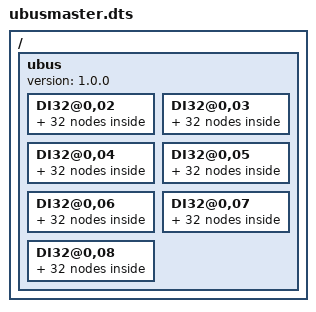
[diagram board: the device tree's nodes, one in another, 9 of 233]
/dts-v1/;
/{
ubus {
	version = "1.0.0";
	DI32@0,02 {
		vname = "0002_DI32/i";
		ts_vname = "DI32@0,02";
		kind = <0x0>;
		 0 { method = <2>; debounce = <10>; T_acc = <0>; N_acc = <2>; T_relax = <50>; invert = <0>; };
		 1 { method = <2>; debounce = <10>; T_acc = <0>; N_acc = <2>; T_relax = <50>; invert = <0>; };
		 2 { method = <2>; debounce = <10>; T_acc = <0>; N_acc = <2>; T_relax = <50>; invert = <0>; };
		 3 { method = <2>; debounce = <10>; T_acc = <0>; N_acc = <2>; T_relax = <50>; invert = <0>; };
		 4 { method = <2>; debounce = <10>; T_acc = <0>; N_acc = <2>; T_relax = <50>; invert = <0>; };
		 5 { method = <2>; debounce = <10>; T_acc = <0>; N_acc = <2>; T_relax = <50>; invert = <0>; };
		 6 { method = <2>; debounce = <10>; T_acc = <0>; N_acc = <2>; T_relax = <50>; invert = <0>; };
		 7 { method = <2>; debounce = <10>; T_acc = <0>; N_acc = <2>; T_relax = <50>; invert = <0>; };
		 8 { method = <2>; debounce = <10>; T_acc = <0>; N_acc = <2>; T_relax = <50>; invert = <0>; };
		 9 { method = <2>; debounce = <10>; T_acc = <0>; N_acc = <2>; T_relax = <50>; invert = <0>; };
		10 { method = <2>; debounce = <10>; T_acc = <0>; N_acc = <2>; T_relax = <50>; invert = <0>; };
		11 { method = <2>; debounce = <10>; T_acc = <0>; N_acc = <2>; T_relax = <50>; invert = <0>; };
		12 { method = <2>; debounce = <10>; T_acc = <0>; N_acc = <2>; T_relax = <50>; invert = <0>; };
		13 { method = <2>; debounce = <10>; T_acc = <0>; N_acc = <2>; T_relax = <50>; invert = <0>; };
		14 { method = <2>; debounce = <10>; T_acc = <0>; N_acc = <2>; T_relax = <50>; invert = <0>; };
		15 { method = <2>; debounce = <10>; T_acc = <0>; N_acc = <2>; T_relax = <50>; invert = <0>; };
		16 { method = <2>; debounce = <10>; T_acc = <0>; N_acc = <2>; T_relax = <50>; invert = <0>; };
		17 { method = <2>; debounce = <10>; T_acc = <0>; N_acc = <2>; T_relax = <50>; invert = <0>; };
		18 { method = <2>; debounce = <10>; T_acc = <0>; N_acc = <2>; T_relax = <50>; invert = <0>; };
		19 { method = <2>; debounce = <10>; T_acc = <0>; N_acc = <2>; T_relax = <50>; invert = <0>; };
		20 { method = <2>; debounce = <10>; T_acc = <0>; N_acc = <2>; T_relax = <50>; invert = <0>; };
		21 { method = <2>; debounce = <10>; T_acc = <0>; N_acc = <2>; T_relax = <50>; invert = <0>; };
		22 { method = <2>; debounce = <10>; T_acc = <0>; N_acc = <2>; T_relax = <50>; invert = <0>; };
		23 { method = <2>; debounce = <10>; T_acc = <0>; N_acc = <2>; T_relax = <50>; invert = <0>; };
		24 { method = <2>; debounce = <10>; T_acc = <0>; N_acc = <2>; T_relax = <50>; invert = <0>; };
		25 { method = <2>; debounce = <10>; T_acc = <0>; N_acc = <2>; T_relax = <50>; invert = <0>; };
		26 { method = <2>; debounce = <10>; T_acc = <0>; N_acc = <2>; T_relax = <50>; invert = <0>; };
		27 { method = <2>; debounce = <10>; T_acc = <0>; N_acc = <2>; T_relax = <50>; invert = <0>; };
		28 { method = <2>; debounce = <10>; T_acc = <0>; N_acc = <2>; T_relax = <50>; invert = <0>; };
		29 { method = <2>; debounce = <10>; T_acc = <0>; N_acc = <2>; T_relax = <50>; invert = <0>; };
		30 { method = <2>; debounce = <10>; T_acc = <0>; N_acc = <2>; T_relax = <50>; invert = <0>; };
		31 { method = <2>; debounce = <10>; T_acc = <0>; N_acc = <2>; T_relax = <50>; invert = <0>; }; };
	DI32@0,03 {
		vname = "0003_DI32/i";
		ts_vname = "DI32@0,03";
		kind = <0x0>;
		 0 { method = <2>; debounce = <10>; T_acc = <0>; N_acc = <2>; T_relax = <50>; invert = <0>; };
		 1 { method = <2>; debounce = <10>; T_acc = <0>; N_acc = <2>; T_relax = <50>; invert = <0>; };
		 2 { method = <2>; debounce = <10>; T_acc = <0>; N_acc = <2>; T_relax = <50>; invert = <0>; };
		 3 { method = <2>; debounce = <10>; T_acc = <0>; N_acc = <2>; T_relax = <50>; invert = <0>; };
		 4 { method = <2>; debounce = <10>; T_acc = <0>; N_acc = <2>; T_relax = <50>; invert = <0>; };
		 5 { method = <2>; debounce = <10>; T_acc = <0>; N_acc = <2>; T_relax = <50>; invert = <0>; };
		 6 { method = <2>; debounce = <10>; T_acc = <0>; N_acc = <2>; T_relax = <50>; invert = <0>; };
		 7 { method = <2>; debounce = <10>; T_acc = <0>; N_acc = <2>; T_relax = <50>; invert = <0>; };
		 8 { method = <2>; debounce = <10>; T_acc = <0>; N_acc = <2>; T_relax = <50>; invert = <0>; };
		 9 { method = <2>; debounce = <10>; T_acc = <0>; N_acc = <2>; T_relax = <50>; invert = <0>; };
		10 { method = <2>; debounce = <10>; T_acc = <0>; N_acc = <2>; T_relax = <50>; invert = <0>; };
		11 { method = <2>; debounce = <10>; T_acc = <0>; N_acc = <2>; T_relax = <50>; invert = <0>; };
		12 { method = <2>; debounce = <10>; T_acc = <0>; N_acc = <2>; T_relax = <50>; invert = <0>; };
		13 { method = <2>; debounce = <10>; T_acc = <0>; N_acc = <2>; T_relax = <50>; invert = <0>; };
		14 { method = <2>; debounce = <10>; T_acc = <0>; N_acc = <2>; T_relax = <50>; invert = <0>; };
		15 { method = <2>; debounce = <10>; T_acc = <0>; N_acc = <2>; T_relax = <50>; invert = <0>; };
		16 { method = <2>; debounce = <10>; T_acc = <0>; N_acc = <2>; T_relax = <50>; invert = <0>; };
		17 { method = <2>; debounce = <10>; T_acc = <0>; N_acc = <2>; T_relax = <50>; invert = <0>; };
		18 { method = <2>; debounce = <10>; T_acc = <0>; N_acc = <2>; T_relax = <50>; invert = <0>; };
		19 { method = <2>; debounce = <10>; T_acc = <0>; N_acc = <2>; T_relax = <50>; invert = <0>; };
		20 { method = <2>; debounce = <10>; T_acc = <0>; N_acc = <2>; T_relax = <50>; invert = <0>; };
		21 { method = <2>; debounce = <10>; T_acc = <0>; N_acc = <2>; T_relax = <50>; invert = <0>; };
		22 { method = <2>; debounce = <10>; T_acc = <0>; N_acc = <2>; T_relax = <50>; invert = <0>; };
		23 { method = <2>; debounce = <10>; T_acc = <0>; N_acc = <2>; T_relax = <50>; invert = <0>; };
		24 { method = <2>; debounce = <10>; T_acc = <0>; N_acc = <2>; T_relax = <50>; invert = <0>; };
		25 { method = <2>; debounce = <10>; T_acc = <0>; N_acc = <2>; T_relax = <50>; invert = <0>; };
		26 { method = <2>; debounce = <10>; T_acc = <0>; N_acc = <2>; T_relax = <50>; invert = <0>; };
		27 { method = <2>; debounce = <10>; T_acc = <0>; N_acc = <2>; T_relax = <50>; invert = <0>; };
		28 { method = <2>; debounce = <10>; T_acc = <0>; N_acc = <2>; T_relax = <50>; invert = <0>; };
		29 { method = <2>; debounce = <10>; T_acc = <0>; N_acc = <2>; T_relax = <50>; invert = <0>; };
		30 { method = <2>; debounce = <10>; T_acc = <0>; N_acc = <2>; T_relax = <50>; invert = <0>; };
		31 { method = <2>; debounce = <10>; T_acc = <0>; N_acc = <2>; T_relax = <50>; invert = <0>; }; };
	DI32@0,04 {
		vname = "0004_DI32/i";
		ts_vname = "DI32@0,04";
		kind = <0x0>;
		 0 { method = <2>; debounce = <10>; T_acc = <0>; N_acc = <2>; T_relax = <50>; invert = <0>; };
		 1 { method = <2>; debounce = <10>; T_acc = <0>; N_acc = <2>; T_relax = <50>; invert = <0>; };
		 2 { method = <2>; debounce = <10>; T_acc = <0>; N_acc = <2>; T_relax = <50>; invert = <0>; };
		 3 { method = <2>; debounce = <10>; T_acc = <0>; N_acc = <2>; T_relax = <50>; invert = <0>; };
		 4 { method = <2>; debounce = <10>; T_acc = <0>; N_acc = <2>; T_relax = <50>; invert = <0>; };
		 5 { method = <2>; debounce = <10>; T_acc = <0>; N_acc = <2>; T_relax = <50>; invert = <0>; };
		 6 { method = <2>; debounce = <10>; T_acc = <0>; N_acc = <2>; T_relax = <50>; invert = <0>; };
		 7 { method = <2>; debounce = <10>; T_acc = <0>; N_acc = <2>; T_relax = <50>; invert = <0>; };
		 8 { method = <2>; debounce = <10>; T_acc = <0>; N_acc = <2>; T_relax = <50>; invert = <0>; };
		 9 { method = <2>; debounce = <200>; T_acc = <0>; N_acc = <2>; T_relax = <50>; invert = <0>; };
		10 { method = <2>; debounce = <10>; T_acc = <0>; N_acc = <2>; T_relax = <50>; invert = <0>; };
		11 { method = <2>; debounce = <10>; T_acc = <0>; N_acc = <2>; T_relax = <50>; invert = <0>; };
		12 { method = <2>; debounce = <10>; T_acc = <0>; N_acc = <2>; T_relax = <50>; invert = <0>; };
		13 { method = <2>; debounce = <10>; T_acc = <0>; N_acc = <2>; T_relax = <50>; invert = <0>; };
		14 { method = <2>; debounce = <10>; T_acc = <0>; N_acc = <2>; T_relax = <50>; invert = <0>; };
		15 { method = <2>; debounce = <10>; T_acc = <0>; N_acc = <2>; T_relax = <50>; invert = <0>; };
		16 { method = <2>; debounce = <10>; T_acc = <0>; N_acc = <2>; T_relax = <50>; invert = <0>; };
		17 { method = <2>; debounce = <10>; T_acc = <0>; N_acc = <2>; T_relax = <50>; invert = <0>; };
		18 { method = <2>; debounce = <10>; T_acc = <0>; N_acc = <2>; T_relax = <50>; invert = <0>; };
		19 { method = <2>; debounce = <10>; T_acc = <0>; N_acc = <2>; T_relax = <50>; invert = <0>; };
		20 { method = <2>; debounce = <200>; T_acc = <0>; N_acc = <2>; T_relax = <50>; invert = <0>; };
		21 { method = <2>; debounce = <10>; T_acc = <0>; N_acc = <2>; T_relax = <50>; invert = <0>; };
		22 { method = <2>; debounce = <10>; T_acc = <0>; N_acc = <2>; T_relax = <50>; invert = <0>; };
		23 { method = <2>; debounce = <10>; T_acc = <0>; N_acc = <2>; T_relax = <50>; invert = <0>; };
		24 { method = <2>; debounce = <10>; T_acc = <0>; N_acc = <2>; T_relax = <50>; invert = <0>; };
		25 { method = <2>; debounce = <10>; T_acc = <0>; N_acc = <2>; T_relax = <50>; invert = <0>; };
		26 { method = <2>; debounce = <10>; T_acc = <0>; N_acc = <2>; T_relax = <50>; invert = <0>; };
		27 { method = <2>; debounce = <10>; T_acc = <0>; N_acc = <2>; T_relax = <50>; invert = <0>; };
		28 { method = <2>; debounce = <10>; T_acc = <0>; N_acc = <2>; T_relax = <50>; invert = <0>; };
		29 { method = <2>; debounce = <10>; T_acc = <0>; N_acc = <2>; T_relax = <50>; invert = <0>; };
		30 { method = <2>; debounce = <10>; T_acc = <0>; N_acc = <2>; T_relax = <50>; invert = <0>; };
		31 { method = <2>; debounce = <10>; T_acc = <0>; N_acc = <2>; T_relax = <50>; invert = <0>; }; };
	DI32@0,05 {
		vname = "0005_DI32/i";
		ts_vname = "DI32@0,05";
		kind = <0x0>;
		 0 { method = <2>; debounce = <10>; T_acc = <0>; N_acc = <2>; T_relax = <50>; invert = <0>; };
		 1 { method = <2>; debounce = <10>; T_acc = <0>; N_acc = <2>; T_relax = <50>; invert = <0>; };
		 2 { method = <2>; debounce = <10>; T_acc = <0>; N_acc = <2>; T_relax = <50>; invert = <0>; };
		 3 { method = <2>; debounce = <10>; T_acc = <0>; N_acc = <2>; T_relax = <50>; invert = <0>; };
		 4 { method = <2>; debounce = <10>; T_acc = <0>; N_acc = <2>; T_relax = <50>; invert = <0>; };
		 5 { method = <2>; debounce = <10>; T_acc = <0>; N_acc = <2>; T_relax = <50>; invert = <0>; };
		 6 { method = <2>; debounce = <10>; T_acc = <0>; N_acc = <2>; T_relax = <50>; invert = <0>; };
		 7 { method = <2>; debounce = <10>; T_acc = <0>; N_acc = <2>; T_relax = <50>; invert = <0>; };
		 8 { method = <2>; debounce = <10>; T_acc = <0>; N_acc = <2>; T_relax = <50>; invert = <0>; };
		 9 { method = <2>; debounce = <10>; T_acc = <0>; N_acc = <2>; T_relax = <50>; invert = <0>; };
		10 { method = <2>; debounce = <10>; T_acc = <0>; N_acc = <2>; T_relax = <50>; invert = <0>; };
		11 { method = <2>; debounce = <10>; T_acc = <0>; N_acc = <2>; T_relax = <50>; invert = <0>; };
		12 { method = <2>; debounce = <10>; T_acc = <0>; N_acc = <2>; T_relax = <50>; invert = <0>; };
		13 { method = <2>; debounce = <10>; T_acc = <0>; N_acc = <2>; T_relax = <50>; invert = <0>; };
		14 { method = <2>; debounce = <10>; T_acc = <0>; N_acc = <2>; T_relax = <50>; invert = <0>; };
		15 { method = <2>; debounce = <10>; T_acc = <0>; N_acc = <2>; T_relax = <50>; invert = <0>; };
		16 { method = <2>; debounce = <10>; T_acc = <0>; N_acc = <2>; T_relax = <50>; invert = <0>; };
		17 { method = <2>; debounce = <10>; T_acc = <0>; N_acc = <2>; T_relax = <50>; invert = <0>; };
		18 { method = <2>; debounce = <10>; T_acc = <0>; N_acc = <2>; T_relax = <50>; invert = <0>; };
		19 { method = <2>; debounce = <10>; T_acc = <0>; N_acc = <2>; T_relax = <50>; invert = <0>; };
		20 { method = <2>; debounce = <10>; T_acc = <0>; N_acc = <2>; T_relax = <50>; invert = <0>; };
		21 { method = <2>; debounce = <10>; T_acc = <0>; N_acc = <2>; T_relax = <50>; invert = <0>; };
		22 { method = <2>; debounce = <10>; T_acc = <0>; N_acc = <2>; T_relax = <50>; invert = <0>; };
		23 { method = <2>; debounce = <10>; T_acc = <0>; N_acc = <2>; T_relax = <50>; invert = <0>; };
		24 { method = <2>; debounce = <10>; T_acc = <0>; N_acc = <2>; T_relax = <50>; invert = <0>; };
		25 { method = <2>; debounce = <10>; T_acc = <0>; N_acc = <2>; T_relax = <50>; invert = <0>; };
		26 { method = <2>; debounce = <10>; T_acc = <0>; N_acc = <2>; T_relax = <50>; invert = <0>; };
		27 { method = <2>; debounce = <10>; T_acc = <0>; N_acc = <2>; T_relax = <50>; invert = <0>; };
		28 { method = <2>; debounce = <10>; T_acc = <0>; N_acc = <2>; T_relax = <50>; invert = <0>; };
		29 { method = <2>; debounce = <10>; T_acc = <0>; N_acc = <2>; T_relax = <50>; invert = <0>; };
		30 { method = <2>; debounce = <10>; T_acc = <0>; N_acc = <2>; T_relax = <50>; invert = <0>; };
		31 { method = <2>; debounce = <10>; T_acc = <0>; N_acc = <2>; T_relax = <50>; invert = <0>; }; };

	DI32@0,06 {
		vname = "0006_DI32/i";
		ts_vname = "DI32@0,06";
		kind = <0x0>;
		 0 { method = <2>; debounce = <10>; T_acc = <0>; N_acc = <2>; T_relax = <50>; invert = <0>; };
		 1 { method = <2>; debounce = <10>; T_acc = <0>; N_acc = <2>; T_relax = <50>; invert = <0>; };
		 2 { method = <2>; debounce = <10>; T_acc = <0>; N_acc = <2>; T_relax = <50>; invert = <0>; };
		 3 { method = <2>; debounce = <10>; T_acc = <0>; N_acc = <2>; T_relax = <50>; invert = <0>; };
		 4 { method = <2>; debounce = <10>; T_acc = <0>; N_acc = <2>; T_relax = <50>; invert = <0>; };
		 5 { method = <2>; debounce = <10>; T_acc = <0>; N_acc = <2>; T_relax = <50>; invert = <0>; };
		 6 { method = <2>; debounce = <10>; T_acc = <0>; N_acc = <2>; T_relax = <50>; invert = <0>; };
		 7 { method = <2>; debounce = <10>; T_acc = <0>; N_acc = <2>; T_relax = <50>; invert = <0>; };
		 8 { method = <2>; debounce = <10>; T_acc = <0>; N_acc = <2>; T_relax = <50>; invert = <0>; };
		 9 { method = <2>; debounce = <10>; T_acc = <0>; N_acc = <2>; T_relax = <50>; invert = <0>; };
		10 { method = <2>; debounce = <10>; T_acc = <0>; N_acc = <2>; T_relax = <50>; invert = <0>; };
		11 { method = <2>; debounce = <10>; T_acc = <0>; N_acc = <2>; T_relax = <50>; invert = <0>; };
		12 { method = <2>; debounce = <10>; T_acc = <0>; N_acc = <2>; T_relax = <50>; invert = <0>; };
		13 { method = <2>; debounce = <10>; T_acc = <0>; N_acc = <2>; T_relax = <50>; invert = <0>; };
		14 { method = <2>; debounce = <10>; T_acc = <0>; N_acc = <2>; T_relax = <50>; invert = <0>; };
		15 { method = <2>; debounce = <10>; T_acc = <0>; N_acc = <2>; T_relax = <50>; invert = <0>; };
		16 { method = <2>; debounce = <10>; T_acc = <0>; N_acc = <2>; T_relax = <50>; invert = <0>; };
		17 { method = <2>; debounce = <10>; T_acc = <0>; N_acc = <2>; T_relax = <50>; invert = <0>; };
		18 { method = <2>; debounce = <10>; T_acc = <0>; N_acc = <2>; T_relax = <50>; invert = <0>; };
		19 { method = <2>; debounce = <10>; T_acc = <0>; N_acc = <2>; T_relax = <50>; invert = <0>; };
		20 { method = <2>; debounce = <10>; T_acc = <0>; N_acc = <2>; T_relax = <50>; invert = <0>; };
		21 { method = <2>; debounce = <10>; T_acc = <0>; N_acc = <2>; T_relax = <50>; invert = <0>; };
		22 { method = <2>; debounce = <10>; T_acc = <0>; N_acc = <2>; T_relax = <50>; invert = <0>; };
		23 { method = <2>; debounce = <10>; T_acc = <0>; N_acc = <2>; T_relax = <50>; invert = <0>; };
		24 { method = <2>; debounce = <10>; T_acc = <0>; N_acc = <2>; T_relax = <50>; invert = <0>; };
		25 { method = <2>; debounce = <10>; T_acc = <0>; N_acc = <2>; T_relax = <50>; invert = <0>; };
		26 { method = <2>; debounce = <10>; T_acc = <0>; N_acc = <2>; T_relax = <50>; invert = <0>; };
		27 { method = <2>; debounce = <10>; T_acc = <0>; N_acc = <2>; T_relax = <50>; invert = <0>; };
		28 { method = <2>; debounce = <10>; T_acc = <0>; N_acc = <2>; T_relax = <50>; invert = <0>; };
		29 { method = <2>; debounce = <10>; T_acc = <0>; N_acc = <2>; T_relax = <50>; invert = <0>; };
		30 { method = <2>; debounce = <10>; T_acc = <0>; N_acc = <2>; T_relax = <50>; invert = <0>; };
		31 { method = <2>; debounce = <10>; T_acc = <0>; N_acc = <2>; T_relax = <50>; invert = <0>; }; };
	DI32@0,07 {
		vname = "0007_DI32/i";
		ts_vname = "DI32@0,07";
		kind = <0x0>;
		 0 { method = <2>; debounce = <10>; T_acc = <0>; N_acc = <2>; T_relax = <50>; invert = <0>; };
		 1 { method = <2>; debounce = <10>; T_acc = <0>; N_acc = <2>; T_relax = <50>; invert = <0>; };
		 2 { method = <2>; debounce = <10>; T_acc = <0>; N_acc = <2>; T_relax = <50>; invert = <0>; };
		 3 { method = <2>; debounce = <10>; T_acc = <0>; N_acc = <2>; T_relax = <50>; invert = <0>; };
		 4 { method = <2>; debounce = <10>; T_acc = <0>; N_acc = <2>; T_relax = <50>; invert = <0>; };
		 5 { method = <2>; debounce = <10>; T_acc = <0>; N_acc = <2>; T_relax = <50>; invert = <0>; };
		 6 { method = <2>; debounce = <10>; T_acc = <0>; N_acc = <2>; T_relax = <50>; invert = <0>; };
		 7 { method = <2>; debounce = <10>; T_acc = <0>; N_acc = <2>; T_relax = <50>; invert = <0>; };
		 8 { method = <2>; debounce = <10>; T_acc = <0>; N_acc = <2>; T_relax = <50>; invert = <0>; };
		 9 { method = <2>; debounce = <10>; T_acc = <0>; N_acc = <2>; T_relax = <50>; invert = <0>; };
		10 { method = <2>; debounce = <10>; T_acc = <0>; N_acc = <2>; T_relax = <50>; invert = <0>; };
		11 { method = <2>; debounce = <10>; T_acc = <0>; N_acc = <2>; T_relax = <50>; invert = <0>; };
		12 { method = <2>; debounce = <10>; T_acc = <0>; N_acc = <2>; T_relax = <50>; invert = <0>; };
		13 { method = <2>; debounce = <10>; T_acc = <0>; N_acc = <2>; T_relax = <50>; invert = <0>; };
		14 { method = <2>; debounce = <10>; T_acc = <0>; N_acc = <2>; T_relax = <50>; invert = <0>; };
		15 { method = <2>; debounce = <10>; T_acc = <0>; N_acc = <2>; T_relax = <50>; invert = <0>; };
		16 { method = <2>; debounce = <10>; T_acc = <0>; N_acc = <2>; T_relax = <50>; invert = <0>; };
		17 { method = <2>; debounce = <10>; T_acc = <0>; N_acc = <2>; T_relax = <50>; invert = <0>; };
		18 { method = <2>; debounce = <10>; T_acc = <0>; N_acc = <2>; T_relax = <50>; invert = <0>; };
		19 { method = <2>; debounce = <10>; T_acc = <0>; N_acc = <2>; T_relax = <50>; invert = <0>; };
		20 { method = <2>; debounce = <10>; T_acc = <0>; N_acc = <2>; T_relax = <50>; invert = <0>; };
		21 { method = <2>; debounce = <10>; T_acc = <0>; N_acc = <2>; T_relax = <50>; invert = <0>; };
		22 { method = <2>; debounce = <10>; T_acc = <0>; N_acc = <2>; T_relax = <50>; invert = <0>; };
		23 { method = <2>; debounce = <10>; T_acc = <0>; N_acc = <2>; T_relax = <50>; invert = <0>; };
		24 { method = <2>; debounce = <10>; T_acc = <0>; N_acc = <2>; T_relax = <50>; invert = <0>; };
		25 { method = <2>; debounce = <10>; T_acc = <0>; N_acc = <2>; T_relax = <50>; invert = <0>; };
		26 { method = <2>; debounce = <10>; T_acc = <0>; N_acc = <2>; T_relax = <50>; invert = <0>; };
		27 { method = <2>; debounce = <10>; T_acc = <0>; N_acc = <2>; T_relax = <50>; invert = <0>; };
		28 { method = <2>; debounce = <10>; T_acc = <0>; N_acc = <2>; T_relax = <50>; invert = <0>; };
		29 { method = <2>; debounce = <10>; T_acc = <0>; N_acc = <2>; T_relax = <50>; invert = <0>; };
		30 { method = <2>; debounce = <10>; T_acc = <0>; N_acc = <2>; T_relax = <50>; invert = <0>; };
		31 { method = <2>; debounce = <10>; T_acc = <0>; N_acc = <2>; T_relax = <50>; invert = <0>; }; };
	DI32@0,08 {
		vname = "0008_DI32/i";
		ts_vname = "DI32@0,08";
		kind = <0x0>;
		 0 { method = <2>; debounce = <10>; T_acc = <0>; N_acc = <2>; T_relax = <50>; invert = <0>; };
		 1 { method = <2>; debounce = <10>; T_acc = <0>; N_acc = <2>; T_relax = <50>; invert = <0>; };
		 2 { method = <2>; debounce = <10>; T_acc = <0>; N_acc = <2>; T_relax = <50>; invert = <0>; };
		 3 { method = <2>; debounce = <10>; T_acc = <0>; N_acc = <2>; T_relax = <50>; invert = <0>; };
		 4 { method = <2>; debounce = <10>; T_acc = <0>; N_acc = <2>; T_relax = <50>; invert = <0>; };
		 5 { method = <2>; debounce = <10>; T_acc = <0>; N_acc = <2>; T_relax = <50>; invert = <0>; };
		 6 { method = <2>; debounce = <10>; T_acc = <0>; N_acc = <2>; T_relax = <50>; invert = <0>; };
		 7 { method = <2>; debounce = <10>; T_acc = <0>; N_acc = <2>; T_relax = <50>; invert = <0>; };
		 8 { method = <2>; debounce = <10>; T_acc = <0>; N_acc = <2>; T_relax = <50>; invert = <0>; };
		 9 { method = <2>; debounce = <10>; T_acc = <0>; N_acc = <2>; T_relax = <50>; invert = <0>; };
		10 { method = <2>; debounce = <10>; T_acc = <0>; N_acc = <2>; T_relax = <50>; invert = <0>; };
		11 { method = <2>; debounce = <10>; T_acc = <0>; N_acc = <2>; T_relax = <50>; invert = <0>; };
		12 { method = <2>; debounce = <10>; T_acc = <0>; N_acc = <2>; T_relax = <50>; invert = <0>; };
		13 { method = <2>; debounce = <10>; T_acc = <0>; N_acc = <2>; T_relax = <50>; invert = <0>; };
		14 { method = <2>; debounce = <10>; T_acc = <0>; N_acc = <2>; T_relax = <50>; invert = <0>; };
		15 { method = <2>; debounce = <10>; T_acc = <0>; N_acc = <2>; T_relax = <50>; invert = <0>; };
		16 { method = <2>; debounce = <10>; T_acc = <0>; N_acc = <2>; T_relax = <50>; invert = <0>; };
		17 { method = <2>; debounce = <10>; T_acc = <0>; N_acc = <2>; T_relax = <50>; invert = <0>; };
		18 { method = <2>; debounce = <10>; T_acc = <0>; N_acc = <2>; T_relax = <50>; invert = <0>; };
		19 { method = <2>; debounce = <10>; T_acc = <0>; N_acc = <2>; T_relax = <50>; invert = <0>; };
		20 { method = <2>; debounce = <10>; T_acc = <0>; N_acc = <2>; T_relax = <50>; invert = <0>; };
		21 { method = <2>; debounce = <10>; T_acc = <0>; N_acc = <2>; T_relax = <50>; invert = <0>; };
		22 { method = <2>; debounce = <10>; T_acc = <0>; N_acc = <2>; T_relax = <50>; invert = <0>; };
		23 { method = <2>; debounce = <10>; T_acc = <0>; N_acc = <2>; T_relax = <50>; invert = <0>; };
		24 { method = <2>; debounce = <10>; T_acc = <0>; N_acc = <2>; T_relax = <50>; invert = <0>; };
		25 { method = <2>; debounce = <10>; T_acc = <0>; N_acc = <2>; T_relax = <50>; invert = <0>; };
		26 { method = <2>; debounce = <10>; T_acc = <0>; N_acc = <2>; T_relax = <50>; invert = <0>; };
		27 { method = <2>; debounce = <10>; T_acc = <0>; N_acc = <2>; T_relax = <50>; invert = <0>; };
		28 { method = <2>; debounce = <10>; T_acc = <0>; N_acc = <2>; T_relax = <50>; invert = <0>; };
		29 { method = <2>; debounce = <10>; T_acc = <0>; N_acc = <2>; T_relax = <50>; invert = <0>; };
		30 { method = <2>; debounce = <10>; T_acc = <0>; N_acc = <2>; T_relax = <50>; invert = <0>; };
		31 { method = <2>; debounce = <10>; T_acc = <0>; N_acc = <2>; T_relax = <50>; invert = <0>; }; };
};
};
